LIN_description_file;
LIN_protocol_version = "2.1";
LIN_language_version = "2.1";
LIN_speed = 19.2 kbps;
Channel_name = "LDFMasterNode";

Nodes {
  Master: LDFMasterNode, 5 ms, 1.5 ms ;
  Slaves: SOV_L, SOV_T, IXV ;
}

Signals {
  SOV_L_TargetPos: 16, 0, LDFMasterNode, SOV_L ;
  SOV_L_DiagFunctnValue: 3, 0, LDFMasterNode, SOV_L ;
  SOV_L_BlockDetEnbl: 2, 0, LDFMasterNode, SOV_L ;
  SOV_L_Reserved1: 3, 0, LDFMasterNode, SOV_L ;
  SOV_L_Reserved2: 8, 0, LDFMasterNode, SOV_L ;
  SOV_L_Reserved3: 8, 0, LDFMasterNode, SOV_L ;
  SOV_L_Reserved4: 8, 0, LDFMasterNode, SOV_L ;
  SOV_L_Reserved5: 8, 0, LDFMasterNode, SOV_L ;
  SOV_L_Reserved6: 8, 0, LDFMasterNode, SOV_L ;
  SOV_T_TargetPos: 16, 0, LDFMasterNode, SOV_T ;
  SOV_T_DiagFunctnValue: 3, 0, LDFMasterNode, SOV_T ;
  SOV_T_BlockDetEnbl: 2, 0, LDFMasterNode, SOV_T ;
  SOV_T_Reserved1: 3, 0, LDFMasterNode, SOV_T ;
  SOV_T_Reserved2: 8, 0, LDFMasterNode, SOV_T ;
  SOV_T_Reserved3: 8, 0, LDFMasterNode, SOV_T ;
  SOV_T_Reserved4: 8, 0, LDFMasterNode, SOV_T ;
  SOV_T_Reserved5: 8, 0, LDFMasterNode, SOV_T ;
  SOV_T_Reserved6: 8, 0, LDFMasterNode, SOV_T ;
  IXV_TargetPos: 16, 0, LDFMasterNode, IXV ;
  IXV_DiagFunctnValue: 3, 0, LDFMasterNode, IXV ;
  IXV_BlockDetEnbl: 2, 0, LDFMasterNode, IXV ;
  IXV_Reserved1: 3, 0, LDFMasterNode, IXV ;
  IXV_Reserved2: 8, 0, LDFMasterNode, IXV ;
  IXV_Reserved3: 8, 0, LDFMasterNode, IXV ;
  IXV_Reserved4: 8, 0, LDFMasterNode, IXV ;
  IXV_Reserved5: 8, 0, LDFMasterNode, IXV ;
  IXV_Reserved6: 8, 0, LDFMasterNode, IXV ;
  SOV_L_SystemState: 2, 0, SOV_L, LDFMasterNode ;
  SOV_L_SelfCalRqd: 1, 0, SOV_L, LDFMasterNode ;
  SOV_L_PositionError: 3, 0, SOV_L, LDFMasterNode ;
  SOV_L_CommsError: 2, 0, SOV_L, LDFMasterNode ;
  SOV_L_EcuVoltage: 8, 0, SOV_L, LDFMasterNode ;
  SOV_L_SlaveTrgtPos: 16, 0, SOV_L, LDFMasterNode ;
  SOV_L_SlaveActPos: 16, 0, SOV_L, LDFMasterNode ;
  SOV_L_EcuTemperature: 8, 0, SOV_L, LDFMasterNode ;
  SOV_L_RespError: 1, 0, SOV_L, LDFMasterNode ;
  SOV_L_EcuError: 2, 0, SOV_L, LDFMasterNode ;
  SOV_L_VoltageError: 2, 0, SOV_L, LDFMasterNode ;
  SOV_L_MotorError: 3, 0, SOV_L, LDFMasterNode ;
  SOV_T_SystemState: 2, 0, SOV_T, LDFMasterNode ;
  SOV_T_SelfCalRqd: 1, 0, SOV_T, LDFMasterNode ;
  SOV_T_PositionError: 3, 0, SOV_T, LDFMasterNode ;
  SOV_T_CommsError: 2, 0, SOV_T, LDFMasterNode ;
  SOV_T_EcuVoltage: 8, 0, SOV_T, LDFMasterNode ;
  SOV_T_SlaveTrgtPos: 16, 0, SOV_T, LDFMasterNode ;
  SOV_T_SlaveActPos: 16, 0, SOV_T, LDFMasterNode ;
  SOV_T_EcuTemperature: 8, 0, SOV_T, LDFMasterNode ;
  SOV_T_RespError: 1, 0, SOV_T, LDFMasterNode ;
  SOV_T_EcuError: 2, 0, SOV_T, LDFMasterNode ;
  SOV_T_VoltageError: 2, 0, SOV_T, LDFMasterNode ;
  SOV_T_MotorError: 3, 0, SOV_T, LDFMasterNode ;
  IXV_SystemState: 2, 0, IXV, LDFMasterNode ;
  IXV_SelfCalRqd: 1, 0, IXV, LDFMasterNode ;
  IXV_PositionError: 3, 0, IXV, LDFMasterNode ;
  IXV_CommsError: 2, 0, IXV, LDFMasterNode ;
  IXV_EcuVoltage: 8, 0, IXV, LDFMasterNode ;
  IXV_SlaveTrgtPos: 16, 0, IXV, LDFMasterNode ;
  IXV_SlaveActPos: 16, 0, IXV, LDFMasterNode ;
  IXV_EcuTemperature: 8, 0, IXV, LDFMasterNode ;
  IXV_RespError: 1, 0, IXV, LDFMasterNode ;
  IXV_EcuError: 2, 0, IXV, LDFMasterNode ;
  IXV_VoltageError: 2, 0, IXV, LDFMasterNode ;
  IXV_MotorError: 3, 0, IXV, LDFMasterNode ;
}

Frames {
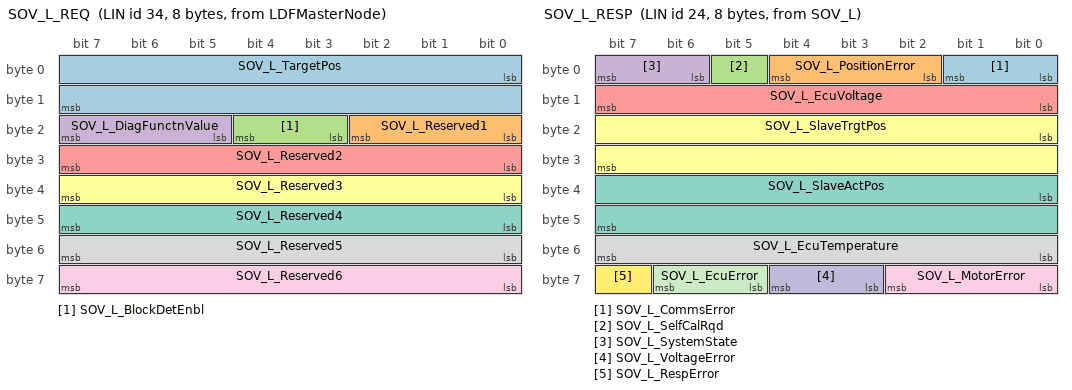
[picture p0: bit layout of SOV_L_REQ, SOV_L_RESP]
  SOV_L_REQ: 34, LDFMasterNode, 8 {
    SOV_L_TargetPos, 0 ;
    SOV_L_Reserved1, 16 ;
    SOV_L_BlockDetEnbl, 19 ;
    SOV_L_DiagFunctnValue, 21 ;
    SOV_L_Reserved2, 24 ;
    SOV_L_Reserved3, 32 ;
    SOV_L_Reserved4, 40 ;
    SOV_L_Reserved5, 48 ;
    SOV_L_Reserved6, 56 ;
  }
  SOV_L_RESP: 24, SOV_L, 8 {
    SOV_L_CommsError, 0 ;
    SOV_L_PositionError, 2 ;
    SOV_L_SelfCalRqd, 5 ;
    SOV_L_SystemState, 6 ;
    SOV_L_EcuVoltage, 8 ;
    SOV_L_SlaveTrgtPos, 16 ;
    SOV_L_SlaveActPos, 32 ;
    SOV_L_EcuTemperature, 48 ;
    SOV_L_MotorError, 56 ;
    SOV_L_VoltageError, 59 ;
    SOV_L_EcuError, 61 ;
    SOV_L_RespError, 63 ;
  }
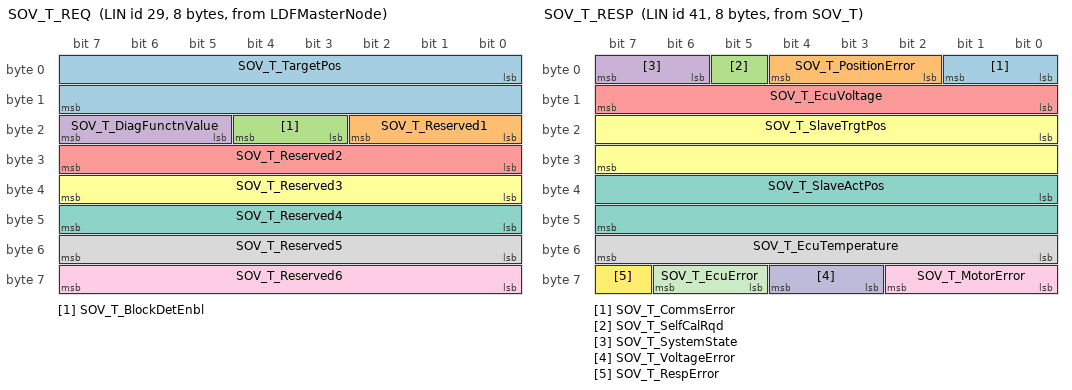
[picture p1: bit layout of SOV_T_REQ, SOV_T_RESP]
  SOV_T_REQ: 29, LDFMasterNode, 8 {
    SOV_T_TargetPos, 0 ;
    SOV_T_Reserved1, 16 ;
    SOV_T_BlockDetEnbl, 19 ;
    SOV_T_DiagFunctnValue, 21 ;
    SOV_T_Reserved2, 24 ;
    SOV_T_Reserved3, 32 ;
    SOV_T_Reserved4, 40 ;
    SOV_T_Reserved5, 48 ;
    SOV_T_Reserved6, 56 ;
  }
  SOV_T_RESP: 41, SOV_T, 8 {
    SOV_T_CommsError, 0 ;
    SOV_T_PositionError, 2 ;
    SOV_T_SelfCalRqd, 5 ;
    SOV_T_SystemState, 6 ;
    SOV_T_EcuVoltage, 8 ;
    SOV_T_SlaveTrgtPos, 16 ;
    SOV_T_SlaveActPos, 32 ;
    SOV_T_EcuTemperature, 48 ;
    SOV_T_MotorError, 56 ;
    SOV_T_VoltageError, 59 ;
    SOV_T_EcuError, 61 ;
    SOV_T_RespError, 63 ;
  }
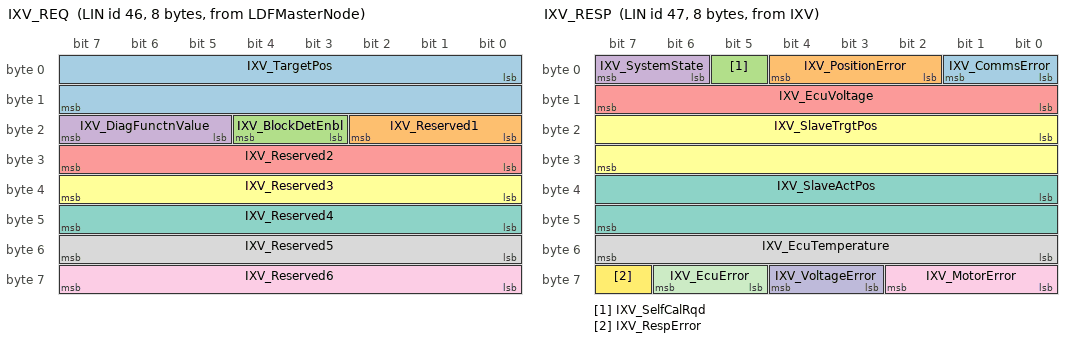
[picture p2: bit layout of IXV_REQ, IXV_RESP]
  IXV_REQ: 46, LDFMasterNode, 8 {
    IXV_TargetPos, 0 ;
    IXV_Reserved1, 16 ;
    IXV_BlockDetEnbl, 19 ;
    IXV_DiagFunctnValue, 21 ;
    IXV_Reserved2, 24 ;
    IXV_Reserved3, 32 ;
    IXV_Reserved4, 40 ;
    IXV_Reserved5, 48 ;
    IXV_Reserved6, 56 ;
  }
  IXV_RESP: 47, IXV, 8 {
    IXV_CommsError, 0 ;
    IXV_PositionError, 2 ;
    IXV_SelfCalRqd, 5 ;
    IXV_SystemState, 6 ;
    IXV_EcuVoltage, 8 ;
    IXV_SlaveTrgtPos, 16 ;
    IXV_SlaveActPos, 32 ;
    IXV_EcuTemperature, 48 ;
    IXV_MotorError, 56 ;
    IXV_VoltageError, 59 ;
    IXV_EcuError, 61 ;
    IXV_RespError, 63 ;
  }
}

Node_attributes {
  SOV_L{
    LIN_protocol = "2.1" ;
    configured_NAD = 0x40 ;
    initial_NAD = 0x40 ;
    product_id = 0x102, 0x1, 0 ;
    response_error = SOV_L_RespError ;
    P2_min = 150 ms ;
    ST_min = 50 ms ;
    N_As_timeout = 1000 ms ;
    N_Cr_timeout = 1000 ms ;
    configurable_frames {
      SOV_L_REQ ;
      SOV_L_RESP ;
    }
  }
  SOV_T{
    LIN_protocol = "2.1" ;
    configured_NAD = 0x41 ;
    initial_NAD = 0x41 ;
    product_id = 0x102, 0x1, 0 ;
    response_error = SOV_T_RespError ;
    P2_min = 150 ms ;
    ST_min = 50 ms ;
    N_As_timeout = 1000 ms ;
    N_Cr_timeout = 1000 ms ;
    configurable_frames {
      SOV_T_REQ ;
      SOV_T_RESP ;
    }
  }
  IXV{
    LIN_protocol = "2.1" ;
    configured_NAD = 0x42 ;
    initial_NAD = 0x42 ;
    product_id = 0x102, 0x1, 0 ;
    response_error = IXV_RespError ;
    P2_min = 150 ms ;
    ST_min = 50 ms ;
    N_As_timeout = 1000 ms ;
    N_Cr_timeout = 1000 ms ;
    configurable_frames {
      IXV_REQ ;
      IXV_RESP ;
    }
  }
}

Schedule_tables {
 Normal_Table {
    SOV_L_REQ delay 30 ms ;
    SOV_L_RESP delay 30 ms ;
    SOV_T_REQ delay 30 ms ;
    SOV_T_RESP delay 30 ms ;
    IXV_REQ delay 30 ms ;
    IXV_RESP delay 30 ms ;
  }
}

Signal_encoding_types {
  BlockCmd {
    logical_value, 0, "Detection Off" ;
    logical_value, 1, "Detection On" ;
    logical_value, 2, "Reserved" ;
    logical_value, 3, "Invalid" ;
  }
  CommsError {
    logical_value, 0, "No Errors" ;
    logical_value, 1, "LIN Comms Response Error" ;
    logical_value, 2, "LIN Comms Response Timeout" ;
    logical_value, 3, "Reserved" ;
  }
  DeviceTemp {
    physical_value, 0, 255, 1, -40, "DegC" ;
  }
  DeviceVoltage {
    physical_value, 0, 255, 0.125, 0, "Volts" ;
  }
  FunctionValue {
    logical_value, 0, "Allow Normal Operation" ;
    logical_value, 1, "Inhibit Self-Calibration" ;
    logical_value, 2, "Force Clear Errors" ;
    logical_value, 3, "Force Self-Calibration" ;
    logical_value, 4, "Force Reset" ;
    logical_value, 5, "1 Point Init Close" ;
    logical_value, 6, "1 Point Init Open" ;
    logical_value, 7, "Reserved" ;
  }
  McuError {
    logical_value, 0, "No Error" ;
    logical_value, 1, "Core Error" ;
    logical_value, 2, "Watchdog Timeout" ;
    logical_value, 3, "Core and Watchdog Timeout" ;
  }
  MtrError {
    logical_value, 0, "No Error" ;
    logical_value, 1, "Open Circuit" ;
    logical_value, 2, "Short Circuit to VBatt" ;
    logical_value, 3, "Short Circuit to Ground" ;
    logical_value, 4, "FET Over Temperature" ;
    logical_value, 5, "FET Under Temperature" ;
    logical_value, 6, "FET Over Current" ;
    logical_value, 7, "Reserved" ;
  }
  PosError {
    logical_value, 0, "No Error" ;
    logical_value, 1, "Re-Referencing in Progress" ;
    logical_value, 2, "Stall Detected - Reduced Range" ;
    logical_value, 3, "End-Stop Not Detected" ;
    logical_value, 4, "Self-Calibration Error" ;
    logical_value, 5, "Reserved" ;
    logical_value, 6, "Reserved" ;
    logical_value, 7, "Reserved" ;
  }
  RespError {
    logical_value, 0, "No Error" ;
    logical_value, 1, "LIN Response Error" ;
  }
  SelfCalibration {
    logical_value, 0, "No Self-Calibration Required" ;
    logical_value, 1, "Self-Calibration Required" ;
  }
  SysState {
    logical_value, 0, "Normal" ;
    logical_value, 1, "Error" ;
    logical_value, 2, "Calibrating" ;
    logical_value, 3, "Sleep" ;
  }
  ValvePostn {
    physical_value, 0, 65535, 0.001526, 0, "%" ;
  }
  VoltError {
    logical_value, 0, "No Error" ;
    logical_value, 1, "Voltage Below Range" ;
    logical_value, 2, "Voltage Above Range" ;
    logical_value, 3, "Reserved" ;
  }
}

Signal_representation {
  BlockCmd: SOV_L_BlockDetEnbl, SOV_T_BlockDetEnbl, IXV_BlockDetEnbl ;
  CommsError: SOV_L_CommsError, SOV_T_CommsError, IXV_CommsError ;
  DeviceTemp: SOV_L_EcuTemperature, SOV_T_EcuTemperature, IXV_EcuTemperature ;
  DeviceVoltage: SOV_L_EcuVoltage, SOV_T_EcuVoltage, IXV_EcuVoltage ;
  FunctionValue: SOV_L_DiagFunctnValue, SOV_T_DiagFunctnValue, IXV_DiagFunctnValue ;
  McuError: SOV_L_EcuError, SOV_T_EcuError, IXV_EcuError ;
  MtrError: SOV_L_MotorError, SOV_T_MotorError, IXV_MotorError ;
  PosError: SOV_L_PositionError, SOV_T_PositionError, IXV_PositionError ;
  RespError: SOV_L_RespError, SOV_T_RespError, IXV_RespError ;
  SelfCalibration: SOV_L_SelfCalRqd, SOV_T_SelfCalRqd, IXV_SelfCalRqd ;
  SysState: SOV_L_SystemState, SOV_T_SystemState, IXV_SystemState ;
  ValvePostn: SOV_L_TargetPos, SOV_T_TargetPos, IXV_TargetPos, SOV_L_SlaveTrgtPos, SOV_L_SlaveActPos, SOV_T_SlaveTrgtPos, SOV_T_SlaveActPos, IXV_SlaveTrgtPos, IXV_SlaveActPos ;
  VoltError: SOV_L_VoltageError, SOV_T_VoltageError, IXV_VoltageError ;
}
